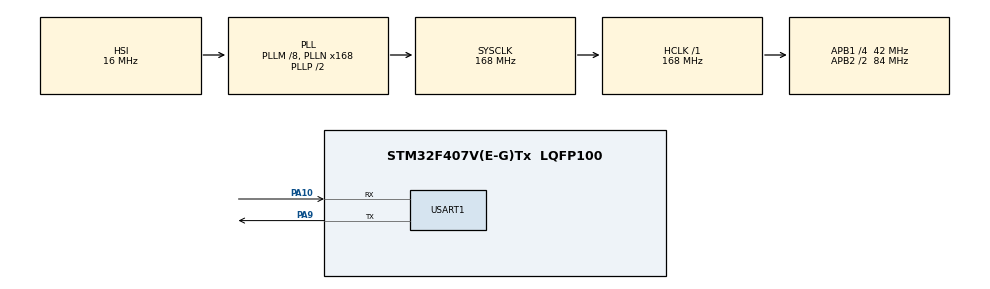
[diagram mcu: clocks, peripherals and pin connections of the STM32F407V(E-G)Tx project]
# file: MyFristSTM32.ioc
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FREERTOS.Mutexes01=UartMutex,Dynamic,NULL,Available
FREERTOS.Queues01=MyQueue,10,uint32_t,0,Dynamic,NULL,NULL
FREERTOS.Tasks01=Tasks_UART,24,256,StartDefaultTask,Default,NULL,Dynamic,NULL,NULL;Task_HeartBeat,8,256,StartTask02,Default,NULL,Dynamic,NULL,NULL
Mcu.Family=STM32F4
Mcu.Name=STM32F407V(E-G)Tx
Mcu.Package=LQFP100
NVIC.PriorityGroup=NVIC_PRIORITYGROUP_4
NVIC.TIM6_DAC_IRQn=true\:15\:0\:false\:false\:true\:false\:false\:true\:true
NVIC.TimeBase=TIM6_DAC_IRQn
NVIC.TimeBaseIP=TIM6
PA10.Mode=Asynchronous
PA10.Signal=USART1_RX
PA13.Mode=Serial_Wire
PA13.Signal=SYS_JTMS-SWDIO
PA14.Mode=Serial_Wire
PA14.Signal=SYS_JTCK-SWCLK
PA9.Mode=Asynchronous
PA9.Signal=USART1_TX
PH0-OSC_IN.Mode=HSE-External-Oscillator
PH0-OSC_IN.Signal=RCC_OSC_IN
PH1-OSC_OUT.Mode=HSE-External-Oscillator
PH1-OSC_OUT.Signal=RCC_OSC_OUT
ProjectManager.HeapSize=0x200
ProjectManager.StackSize=0x400
ProjectManager.TargetToolchain=STM32CubeIDE
RCC.48MHZClocksFreq_Value=84000000
RCC.AHBFreq_Value=168000000
RCC.APB1CLKDivider=RCC_HCLK_DIV4
RCC.APB1Freq_Value=42000000
RCC.APB1TimFreq_Value=84000000
RCC.APB2CLKDivider=RCC_HCLK_DIV2
RCC.APB2Freq_Value=84000000
RCC.APB2TimFreq_Value=168000000
RCC.CortexFreq_Value=168000000
RCC.HCLKFreq_Value=168000000
RCC.HSE_VALUE=25000000
RCC.HSI_VALUE=16000000
RCC.LSE_VALUE=32768
RCC.PLLM=8
RCC.PLLN=168
RCC.SYSCLKFreq_VALUE=168000000
RCC.SYSCLKSource=RCC_SYSCLKSOURCE_PLLCLK
RCC.VCOOutputFreq_Value=336000000
USART1.VirtualMode=VM_ASYNC
VP_FREERTOS_VS_CMSIS_V2.Mode=CMSIS_V2
VP_SYS_VS_tim6.Mode=TIM6
board=custom

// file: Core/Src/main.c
/* USER CODE BEGIN Header */
/**
  ******************************************************************************
  * @file           : main.c
  * @brief          : Main program body
  ******************************************************************************
  * @attention
  *
  * Copyright (c) 2026 STMicroelectronics.
  * All rights reserved.
  *
  * This software is licensed under terms that can be found in the LICENSE file
  * in the root directory of this software component.
  * If no LICENSE file comes with this software, it is provided AS-IS.
  *
  ******************************************************************************
  */
/* USER CODE END Header */
#include "main.h"
#include "cmsis_os.h"

/* USER CODE BEGIN Includes */
#include <stdio.h>
#include <string.h>
/* USER CODE END Includes */

UART_HandleTypeDef huart1;

/* Definitions for Tasks_UART */
osThreadId_t Tasks_UARTHandle;
const osThreadAttr_t Tasks_UART_attributes = {
  .name = "Tasks_UART",
  .stack_size = 256 * 4,
  .priority = (osPriority_t) osPriorityNormal,
};
/* Definitions for Task_HeartBeat */
osThreadId_t Task_HeartBeatHandle;
const osThreadAttr_t Task_HeartBeat_attributes = {
  .name = "Task_HeartBeat",
  .stack_size = 256 * 4,
  .priority = (osPriority_t) osPriorityLow,
};
/* Definitions for MyQueue */
osMessageQueueId_t MyQueueHandle;
const osMessageQueueAttr_t MyQueue_attributes = {
  .name = "MyQueue"
};
/* Definitions for UartMutex */
osMutexId_t UartMutexHandle;
const osMutexAttr_t UartMutex_attributes = {
  .name = "UartMutex"
};

void SystemClock_Config(void);
static void MX_GPIO_Init(void);
static void MX_USART1_UART_Init(void);
void StartDefaultTask(void *argument);
void StartTask02(void *argument);

int main(void)
{

  /* MCU Configuration--------------------------------------------------------*/

  /* Reset of all peripherals, Initializes the Flash interface and the Systick. */
  HAL_Init();

  /* Configure the system clock */
  SystemClock_Config();

  /* Initialize all configured peripherals */
  MX_GPIO_Init();
  MX_USART1_UART_Init();

  /* Init scheduler */
  osKernelInitialize();
  /* Create the mutex(es) */
  /* creation of UartMutex */
  UartMutexHandle = osMutexNew(&UartMutex_attributes);

  /* Create the queue(s) */
  /* creation of MyQueue */
  MyQueueHandle = osMessageQueueNew (10, sizeof(uint32_t), &MyQueue_attributes);

  /* Create the thread(s) */
  /* creation of Tasks_UART */
  Tasks_UARTHandle = osThreadNew(StartDefaultTask, NULL, &Tasks_UART_attributes);

  /* creation of Task_HeartBeat */
  Task_HeartBeatHandle = osThreadNew(StartTask02, NULL, &Task_HeartBeat_attributes);

  /* Start scheduler */
  osKernelStart();

  /* We should never get here as control is now taken by the scheduler */

  /* Infinite loop */
  /* USER CODE BEGIN WHILE */
  int count=0;
  while (1)
  {
    /* USER CODE END WHILE */

  }
}

void SystemClock_Config(void)
{
  RCC_OscInitTypeDef RCC_OscInitStruct = {0};
  RCC_ClkInitTypeDef RCC_ClkInitStruct = {0};

  /** Configure the main internal regulator output voltage
  */
  __HAL_RCC_PWR_CLK_ENABLE();
  __HAL_PWR_VOLTAGESCALING_CONFIG(PWR_REGULATOR_VOLTAGE_SCALE1);

  /** Initializes the RCC Oscillators according to the specified parameters
  * in the RCC_OscInitTypeDef structure.
  */
  RCC_OscInitStruct.OscillatorType = RCC_OSCILLATORTYPE_HSI;
  RCC_OscInitStruct.HSIState = RCC_HSI_ON;
  RCC_OscInitStruct.HSICalibrationValue = RCC_HSICALIBRATION_DEFAULT;
  RCC_OscInitStruct.PLL.PLLState = RCC_PLL_ON;
  RCC_OscInitStruct.PLL.PLLSource = RCC_PLLSOURCE_HSI;
  RCC_OscInitStruct.PLL.PLLM = 8;
  RCC_OscInitStruct.PLL.PLLN = 168;
  RCC_OscInitStruct.PLL.PLLP = RCC_PLLP_DIV2;
  RCC_OscInitStruct.PLL.PLLQ = 4;
  if (HAL_RCC_OscConfig(&RCC_OscInitStruct) != HAL_OK)
  {
    Error_Handler();
  }

  /** Initializes the CPU, AHB and APB buses clocks
  */
  RCC_ClkInitStruct.ClockType = RCC_CLOCKTYPE_HCLK|RCC_CLOCKTYPE_SYSCLK
                              |RCC_CLOCKTYPE_PCLK1|RCC_CLOCKTYPE_PCLK2;
  RCC_ClkInitStruct.SYSCLKSource = RCC_SYSCLKSOURCE_PLLCLK;
  RCC_ClkInitStruct.AHBCLKDivider = RCC_SYSCLK_DIV1;
  RCC_ClkInitStruct.APB1CLKDivider = RCC_HCLK_DIV4;
  RCC_ClkInitStruct.APB2CLKDivider = RCC_HCLK_DIV2;

  if (HAL_RCC_ClockConfig(&RCC_ClkInitStruct, FLASH_LATENCY_5) != HAL_OK)
  {
    Error_Handler();
  }
}

static void MX_USART1_UART_Init(void)
{

  huart1.Instance = USART1;
  huart1.Init.BaudRate = 115200;
  huart1.Init.WordLength = UART_WORDLENGTH_8B;
  huart1.Init.StopBits = UART_STOPBITS_1;
  huart1.Init.Parity = UART_PARITY_NONE;
  huart1.Init.Mode = UART_MODE_TX_RX;
  huart1.Init.HwFlowCtl = UART_HWCONTROL_NONE;
  huart1.Init.OverSampling = UART_OVERSAMPLING_16;
  if (HAL_UART_Init(&huart1) != HAL_OK)
  {
    Error_Handler();
  }

}

static void MX_GPIO_Init(void)
{

  /* GPIO Ports Clock Enable */
  __HAL_RCC_GPIOH_CLK_ENABLE();
  __HAL_RCC_GPIOA_CLK_ENABLE();

}

void StartDefaultTask(void *argument)
{
  /* USER CODE BEGIN 5 */
  /* Infinite loop */
	uint32_t data=0;
	char mrg[50];
  for(;;)
  {

	  osStatus_t status=osMessageQueueGet(MyQueueHandle,&data,NULL,osWaitForever);
	  if(status==osOK){

	  sprintf(mrg,"receive the data:%u\r\n",data);
	  HAL_UART_Transmit(&huart1,(uint8_t*)mrg,strlen(mrg),100);
	  }

  }
  /* USER CODE END 5 */
}

void StartTask02(void *argument)
{
  /* USER CODE BEGIN StartTask02 */
  /* Infinite loop */
	uint32_t count=0;

  for(;;)
  {
	  count++;
	 osStatus_t status=osMessageQueuePut(MyQueueHandle,&count,0,100);
	  if(status==osOK){}
	  osDelay(1000);
  }

  /* USER CODE END StartTask02 */
}

void HAL_TIM_PeriodElapsedCallback(TIM_HandleTypeDef *htim)
{
  if (htim->Instance == TIM6)
  {
    HAL_IncTick();
  }
}

void Error_Handler(void)
{
  __disable_irq();
  while (1)
  {
  }
}
